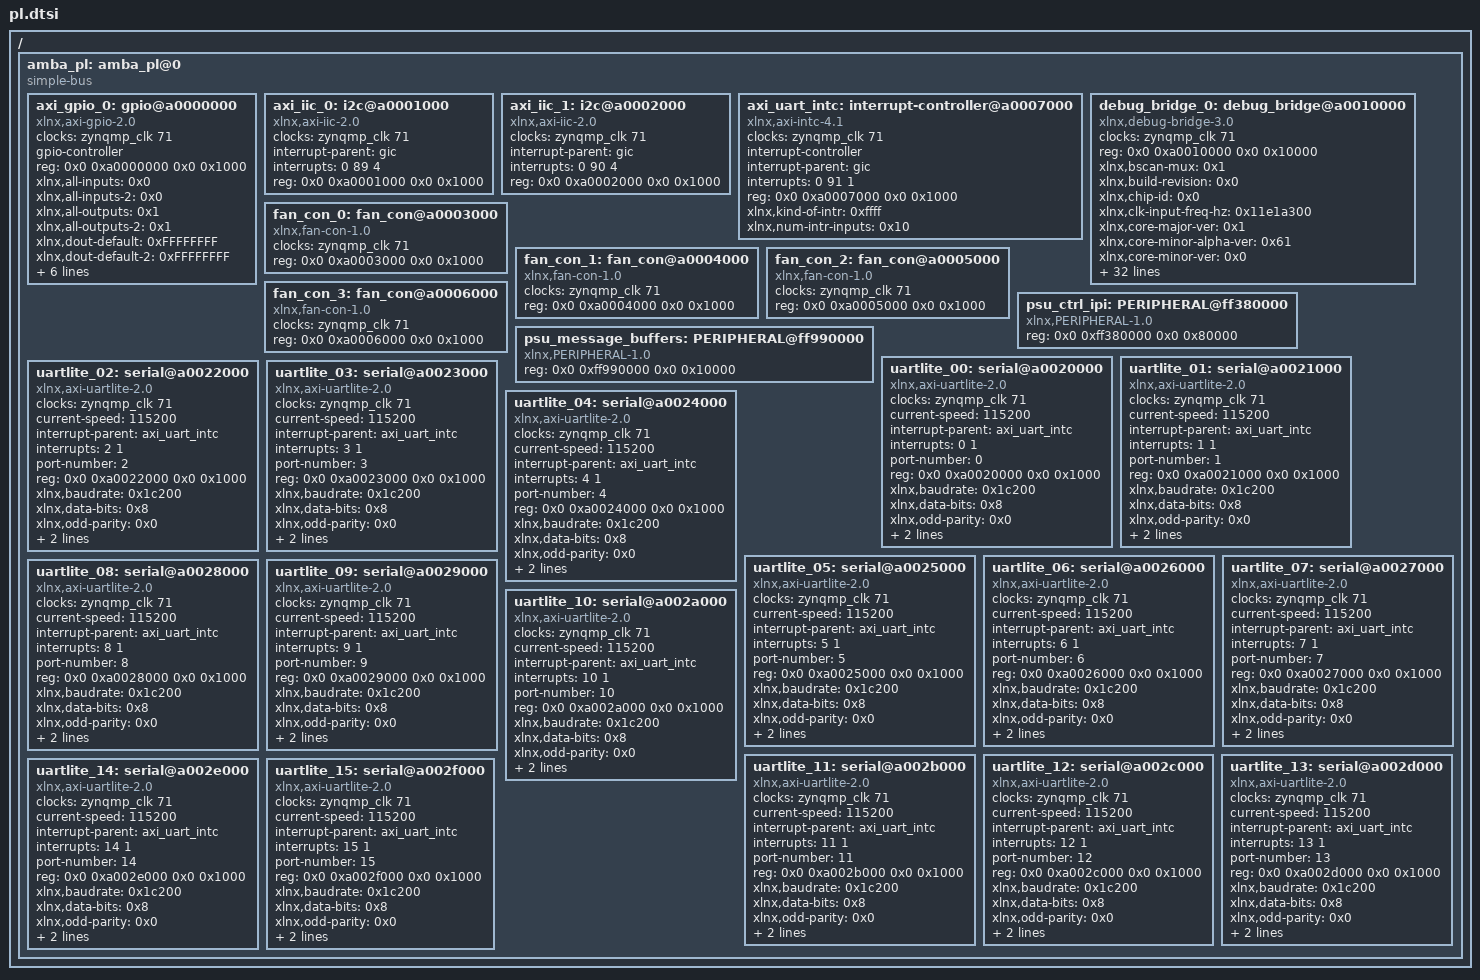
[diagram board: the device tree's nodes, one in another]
/*
 * CAUTION: This file is automatically generated by Xilinx.
 * Version: HSI 2019.1
 * Today is: Wed Dec 30 15:23:14 2020
 */


/ {
	amba_pl: amba_pl@0 {
		#address-cells = <2>;
		#size-cells = <2>;
		compatible = "simple-bus";
		ranges ;
		axi_gpio_0: gpio@a0000000 {
			#gpio-cells = <3>;
			clock-names = "s_axi_aclk";
			clocks = <&zynqmp_clk 71>;
			compatible = "xlnx,axi-gpio-2.0", "xlnx,xps-gpio-1.00.a";
			gpio-controller ;
			reg = <0x0 0xa0000000 0x0 0x1000>;
			xlnx,all-inputs = <0x0>;
			xlnx,all-inputs-2 = <0x0>;
			xlnx,all-outputs = <0x1>;
			xlnx,all-outputs-2 = <0x1>;
			xlnx,dout-default = <0xFFFFFFFF>;
			xlnx,dout-default-2 = <0xFFFFFFFF>;
			xlnx,gpio-width = <0x10>;
			xlnx,gpio2-width = <0x2>;
			xlnx,interrupt-present = <0x0>;
			xlnx,is-dual = <0x1>;
			xlnx,tri-default = <0xFFFFFFFF>;
			xlnx,tri-default-2 = <0xFFFFFFFF>;
		};
		axi_iic_0: i2c@a0001000 {
			#address-cells = <1>;
			#size-cells = <0>;
			clock-names = "s_axi_aclk";
			clocks = <&zynqmp_clk 71>;
			compatible = "xlnx,axi-iic-2.0", "xlnx,xps-iic-2.00.a";
			interrupt-names = "iic2intc_irpt";
			interrupt-parent = <&gic>;
			interrupts = <0 89 4>;
			reg = <0x0 0xa0001000 0x0 0x1000>;
		};
		axi_iic_1: i2c@a0002000 {
			#address-cells = <1>;
			#size-cells = <0>;
			clock-names = "s_axi_aclk";
			clocks = <&zynqmp_clk 71>;
			compatible = "xlnx,axi-iic-2.0", "xlnx,xps-iic-2.00.a";
			interrupt-names = "iic2intc_irpt";
			interrupt-parent = <&gic>;
			interrupts = <0 90 4>;
			reg = <0x0 0xa0002000 0x0 0x1000>;
		};
		axi_uart_intc: interrupt-controller@a0007000 {
			#interrupt-cells = <2>;
			clock-names = "s_axi_aclk";
			clocks = <&zynqmp_clk 71>;
			compatible = "xlnx,axi-intc-4.1", "xlnx,xps-intc-1.00.a";
			interrupt-controller ;
			interrupt-names = "irq";
			interrupt-parent = <&gic>;
			interrupts = <0 91 1>;
			reg = <0x0 0xa0007000 0x0 0x1000>;
			xlnx,kind-of-intr = <0xffff>;
			xlnx,num-intr-inputs = <0x10>;
		};
		debug_bridge_0: debug_bridge@a0010000 {
			/* This is a place holder node for a custom IP, user may need to update the entries */
			clock-names = "s_axi_aclk";
			clocks = <&zynqmp_clk 71>;
			compatible = "xlnx,debug-bridge-3.0";
			reg = <0x0 0xa0010000 0x0 0x10000>;
			xlnx,bscan-mux = <0x1>;
			xlnx,build-revision = <0x0>;
			xlnx,chip-id = <0x0>;
			xlnx,clk-input-freq-hz = <0x11e1a300>;
			xlnx,core-major-ver = <0x1>;
			xlnx,core-minor-alpha-ver = <0x61>;
			xlnx,core-minor-ver = <0x0>;
			xlnx,core-type = <0x1>;
			xlnx,dclk-has-reset = <0x0>;
			xlnx,debug-mode = <0x3>;
			xlnx,design-type = <0x0>;
			xlnx,device-family = <0x0>;
			xlnx,en-bscanid-vec = "false";
			xlnx,en-int-sim = <0x1>;
			xlnx,en-passthrough = <0x0>;
			xlnx,enable-clk-divider = "false";
			xlnx,fifo-style = "SUBCORE";
			xlnx,ir-id-instr = <0x0>;
			xlnx,ir-user1-instr = <0x0>;
			xlnx,ir-width = <0x0>;
			xlnx,major-version = <0xe>;
			xlnx,master-intf-type = <0x1>;
			xlnx,minor-version = <0x1>;
			xlnx,num-bs-master = <0x0>;
			xlnx,pcie-ext-cfg-base-addr = <0x400>;
			xlnx,pcie-ext-cfg-next-ptr = <0x000>;
			xlnx,pcie-ext-cfg-vsec-id = <0x0008>;
			xlnx,pcie-ext-cfg-vsec-length = <0x020>;
			xlnx,pcie-ext-cfg-vsec-rev-id = <0x0>;
			xlnx,tck-clock-ratio = <0x14>;
			xlnx,two-prim-mode = "false";
			xlnx,use-bufr = <0x0>;
			xlnx,use-ext-bscan = "true";
			xlnx,use-softbscan = <0x1>;
			xlnx,use-startup-clk = "false";
			xlnx,user-scan-chain = <0x1>;
			xlnx,xsdb-num-slaves = <0x0>;
			xlnx,xvc-hw-id = <0x0001>;
			xlnx,xvc-sw-id = <0x0001>;
		};
		fan_con_0: fan_con@a0003000 {
			/* This is a place holder node for a custom IP, user may need to update the entries */
			clock-names = "clk_100m";
			clocks = <&zynqmp_clk 71>;
			compatible = "xlnx,fan-con-1.0";
			reg = <0x0 0xa0003000 0x0 0x1000>;
		};
		fan_con_1: fan_con@a0004000 {
			/* This is a place holder node for a custom IP, user may need to update the entries */
			clock-names = "clk_100m";
			clocks = <&zynqmp_clk 71>;
			compatible = "xlnx,fan-con-1.0";
			reg = <0x0 0xa0004000 0x0 0x1000>;
		};
		fan_con_2: fan_con@a0005000 {
			/* This is a place holder node for a custom IP, user may need to update the entries */
			clock-names = "clk_100m";
			clocks = <&zynqmp_clk 71>;
			compatible = "xlnx,fan-con-1.0";
			reg = <0x0 0xa0005000 0x0 0x1000>;
		};
		fan_con_3: fan_con@a0006000 {
			/* This is a place holder node for a custom IP, user may need to update the entries */
			clock-names = "clk_100m";
			clocks = <&zynqmp_clk 71>;
			compatible = "xlnx,fan-con-1.0";
			reg = <0x0 0xa0006000 0x0 0x1000>;
		};
		psu_ctrl_ipi: PERIPHERAL@ff380000 {
			/* This is a place holder node for a custom IP, user may need to update the entries */
			compatible = "xlnx,PERIPHERAL-1.0";
			reg = <0x0 0xff380000 0x0 0x80000>;
		};
		psu_message_buffers: PERIPHERAL@ff990000 {
			/* This is a place holder node for a custom IP, user may need to update the entries */
			compatible = "xlnx,PERIPHERAL-1.0";
			reg = <0x0 0xff990000 0x0 0x10000>;
		};
		uartlite_00: serial@a0020000 {
			clock-names = "s_axi_aclk";
			clocks = <&zynqmp_clk 71>;
			compatible = "xlnx,axi-uartlite-2.0", "xlnx,xps-uartlite-1.00.a";
			current-speed = <115200>;
			device_type = "serial";
			interrupt-names = "interrupt";
			interrupt-parent = <&axi_uart_intc>;
			interrupts = <0 1>;
			port-number = <0>;
			reg = <0x0 0xa0020000 0x0 0x1000>;
			xlnx,baudrate = <0x1c200>;
			xlnx,data-bits = <0x8>;
			xlnx,odd-parity = <0x0>;
			xlnx,s-axi-aclk-freq-hz-d = "99.999001";
			xlnx,use-parity = <0x0>;
		};
		uartlite_01: serial@a0021000 {
			clock-names = "s_axi_aclk";
			clocks = <&zynqmp_clk 71>;
			compatible = "xlnx,axi-uartlite-2.0", "xlnx,xps-uartlite-1.00.a";
			current-speed = <115200>;
			device_type = "serial";
			interrupt-names = "interrupt";
			interrupt-parent = <&axi_uart_intc>;
			interrupts = <1 1>;
			port-number = <1>;
			reg = <0x0 0xa0021000 0x0 0x1000>;
			xlnx,baudrate = <0x1c200>;
			xlnx,data-bits = <0x8>;
			xlnx,odd-parity = <0x0>;
			xlnx,s-axi-aclk-freq-hz-d = "99.999001";
			xlnx,use-parity = <0x0>;
		};
		uartlite_02: serial@a0022000 {
			clock-names = "s_axi_aclk";
			clocks = <&zynqmp_clk 71>;
			compatible = "xlnx,axi-uartlite-2.0", "xlnx,xps-uartlite-1.00.a";
			current-speed = <115200>;
			device_type = "serial";
			interrupt-names = "interrupt";
			interrupt-parent = <&axi_uart_intc>;
			interrupts = <2 1>;
			port-number = <2>;
			reg = <0x0 0xa0022000 0x0 0x1000>;
			xlnx,baudrate = <0x1c200>;
			xlnx,data-bits = <0x8>;
			xlnx,odd-parity = <0x0>;
			xlnx,s-axi-aclk-freq-hz-d = "99.999001";
			xlnx,use-parity = <0x0>;
		};
		uartlite_03: serial@a0023000 {
			clock-names = "s_axi_aclk";
			clocks = <&zynqmp_clk 71>;
			compatible = "xlnx,axi-uartlite-2.0", "xlnx,xps-uartlite-1.00.a";
			current-speed = <115200>;
			device_type = "serial";
			interrupt-names = "interrupt";
			interrupt-parent = <&axi_uart_intc>;
			interrupts = <3 1>;
			port-number = <3>;
			reg = <0x0 0xa0023000 0x0 0x1000>;
			xlnx,baudrate = <0x1c200>;
			xlnx,data-bits = <0x8>;
			xlnx,odd-parity = <0x0>;
			xlnx,s-axi-aclk-freq-hz-d = "99.999001";
			xlnx,use-parity = <0x0>;
		};
		uartlite_04: serial@a0024000 {
			clock-names = "s_axi_aclk";
			clocks = <&zynqmp_clk 71>;
			compatible = "xlnx,axi-uartlite-2.0", "xlnx,xps-uartlite-1.00.a";
			current-speed = <115200>;
			device_type = "serial";
			interrupt-names = "interrupt";
			interrupt-parent = <&axi_uart_intc>;
			interrupts = <4 1>;
			port-number = <4>;
			reg = <0x0 0xa0024000 0x0 0x1000>;
			xlnx,baudrate = <0x1c200>;
			xlnx,data-bits = <0x8>;
			xlnx,odd-parity = <0x0>;
			xlnx,s-axi-aclk-freq-hz-d = "99.999001";
			xlnx,use-parity = <0x0>;
		};
		uartlite_05: serial@a0025000 {
			clock-names = "s_axi_aclk";
			clocks = <&zynqmp_clk 71>;
			compatible = "xlnx,axi-uartlite-2.0", "xlnx,xps-uartlite-1.00.a";
			current-speed = <115200>;
			device_type = "serial";
			interrupt-names = "interrupt";
			interrupt-parent = <&axi_uart_intc>;
			interrupts = <5 1>;
			port-number = <5>;
			reg = <0x0 0xa0025000 0x0 0x1000>;
			xlnx,baudrate = <0x1c200>;
			xlnx,data-bits = <0x8>;
			xlnx,odd-parity = <0x0>;
			xlnx,s-axi-aclk-freq-hz-d = "99.999001";
			xlnx,use-parity = <0x0>;
		};
		uartlite_06: serial@a0026000 {
			clock-names = "s_axi_aclk";
			clocks = <&zynqmp_clk 71>;
			compatible = "xlnx,axi-uartlite-2.0", "xlnx,xps-uartlite-1.00.a";
			current-speed = <115200>;
			device_type = "serial";
			interrupt-names = "interrupt";
			interrupt-parent = <&axi_uart_intc>;
			interrupts = <6 1>;
			port-number = <6>;
			reg = <0x0 0xa0026000 0x0 0x1000>;
			xlnx,baudrate = <0x1c200>;
			xlnx,data-bits = <0x8>;
			xlnx,odd-parity = <0x0>;
			xlnx,s-axi-aclk-freq-hz-d = "99.999001";
			xlnx,use-parity = <0x0>;
		};
		uartlite_07: serial@a0027000 {
			clock-names = "s_axi_aclk";
			clocks = <&zynqmp_clk 71>;
			compatible = "xlnx,axi-uartlite-2.0", "xlnx,xps-uartlite-1.00.a";
			current-speed = <115200>;
			device_type = "serial";
			interrupt-names = "interrupt";
			interrupt-parent = <&axi_uart_intc>;
			interrupts = <7 1>;
			port-number = <7>;
			reg = <0x0 0xa0027000 0x0 0x1000>;
			xlnx,baudrate = <0x1c200>;
			xlnx,data-bits = <0x8>;
			xlnx,odd-parity = <0x0>;
			xlnx,s-axi-aclk-freq-hz-d = "99.999001";
			xlnx,use-parity = <0x0>;
		};
		uartlite_08: serial@a0028000 {
			clock-names = "s_axi_aclk";
			clocks = <&zynqmp_clk 71>;
			compatible = "xlnx,axi-uartlite-2.0", "xlnx,xps-uartlite-1.00.a";
			current-speed = <115200>;
			device_type = "serial";
			interrupt-names = "interrupt";
			interrupt-parent = <&axi_uart_intc>;
			interrupts = <8 1>;
			port-number = <8>;
			reg = <0x0 0xa0028000 0x0 0x1000>;
			xlnx,baudrate = <0x1c200>;
			xlnx,data-bits = <0x8>;
			xlnx,odd-parity = <0x0>;
			xlnx,s-axi-aclk-freq-hz-d = "99.999001";
			xlnx,use-parity = <0x0>;
		};
		uartlite_09: serial@a0029000 {
			clock-names = "s_axi_aclk";
			clocks = <&zynqmp_clk 71>;
			compatible = "xlnx,axi-uartlite-2.0", "xlnx,xps-uartlite-1.00.a";
			current-speed = <115200>;
			device_type = "serial";
			interrupt-names = "interrupt";
			interrupt-parent = <&axi_uart_intc>;
			interrupts = <9 1>;
			port-number = <9>;
			reg = <0x0 0xa0029000 0x0 0x1000>;
			xlnx,baudrate = <0x1c200>;
			xlnx,data-bits = <0x8>;
			xlnx,odd-parity = <0x0>;
			xlnx,s-axi-aclk-freq-hz-d = "99.999001";
			xlnx,use-parity = <0x0>;
		};
		uartlite_10: serial@a002a000 {
			clock-names = "s_axi_aclk";
			clocks = <&zynqmp_clk 71>;
			compatible = "xlnx,axi-uartlite-2.0", "xlnx,xps-uartlite-1.00.a";
			current-speed = <115200>;
			device_type = "serial";
			interrupt-names = "interrupt";
			interrupt-parent = <&axi_uart_intc>;
			interrupts = <10 1>;
			port-number = <10>;
			reg = <0x0 0xa002a000 0x0 0x1000>;
			xlnx,baudrate = <0x1c200>;
			xlnx,data-bits = <0x8>;
			xlnx,odd-parity = <0x0>;
			xlnx,s-axi-aclk-freq-hz-d = "99.999001";
			xlnx,use-parity = <0x0>;
		};
		uartlite_11: serial@a002b000 {
			clock-names = "s_axi_aclk";
			clocks = <&zynqmp_clk 71>;
			compatible = "xlnx,axi-uartlite-2.0", "xlnx,xps-uartlite-1.00.a";
			current-speed = <115200>;
			device_type = "serial";
			interrupt-names = "interrupt";
			interrupt-parent = <&axi_uart_intc>;
			interrupts = <11 1>;
			port-number = <11>;
			reg = <0x0 0xa002b000 0x0 0x1000>;
			xlnx,baudrate = <0x1c200>;
			xlnx,data-bits = <0x8>;
			xlnx,odd-parity = <0x0>;
			xlnx,s-axi-aclk-freq-hz-d = "99.999001";
			xlnx,use-parity = <0x0>;
		};
		uartlite_12: serial@a002c000 {
			clock-names = "s_axi_aclk";
			clocks = <&zynqmp_clk 71>;
			compatible = "xlnx,axi-uartlite-2.0", "xlnx,xps-uartlite-1.00.a";
			current-speed = <115200>;
			device_type = "serial";
			interrupt-names = "interrupt";
			interrupt-parent = <&axi_uart_intc>;
			interrupts = <12 1>;
			port-number = <12>;
			reg = <0x0 0xa002c000 0x0 0x1000>;
			xlnx,baudrate = <0x1c200>;
			xlnx,data-bits = <0x8>;
			xlnx,odd-parity = <0x0>;
			xlnx,s-axi-aclk-freq-hz-d = "99.999001";
			xlnx,use-parity = <0x0>;
		};
		uartlite_13: serial@a002d000 {
			clock-names = "s_axi_aclk";
			clocks = <&zynqmp_clk 71>;
			compatible = "xlnx,axi-uartlite-2.0", "xlnx,xps-uartlite-1.00.a";
			current-speed = <115200>;
			device_type = "serial";
			interrupt-names = "interrupt";
			interrupt-parent = <&axi_uart_intc>;
			interrupts = <13 1>;
			port-number = <13>;
			reg = <0x0 0xa002d000 0x0 0x1000>;
			xlnx,baudrate = <0x1c200>;
			xlnx,data-bits = <0x8>;
			xlnx,odd-parity = <0x0>;
			xlnx,s-axi-aclk-freq-hz-d = "99.999001";
			xlnx,use-parity = <0x0>;
		};
		uartlite_14: serial@a002e000 {
			clock-names = "s_axi_aclk";
			clocks = <&zynqmp_clk 71>;
			compatible = "xlnx,axi-uartlite-2.0", "xlnx,xps-uartlite-1.00.a";
			current-speed = <115200>;
			device_type = "serial";
			interrupt-names = "interrupt";
			interrupt-parent = <&axi_uart_intc>;
			interrupts = <14 1>;
			port-number = <14>;
			reg = <0x0 0xa002e000 0x0 0x1000>;
			xlnx,baudrate = <0x1c200>;
			xlnx,data-bits = <0x8>;
			xlnx,odd-parity = <0x0>;
			xlnx,s-axi-aclk-freq-hz-d = "99.999001";
			xlnx,use-parity = <0x0>;
		};
		uartlite_15: serial@a002f000 {
			clock-names = "s_axi_aclk";
			clocks = <&zynqmp_clk 71>;
			compatible = "xlnx,axi-uartlite-2.0", "xlnx,xps-uartlite-1.00.a";
			current-speed = <115200>;
			device_type = "serial";
			interrupt-names = "interrupt";
			interrupt-parent = <&axi_uart_intc>;
			interrupts = <15 1>;
			port-number = <15>;
			reg = <0x0 0xa002f000 0x0 0x1000>;
			xlnx,baudrate = <0x1c200>;
			xlnx,data-bits = <0x8>;
			xlnx,odd-parity = <0x0>;
			xlnx,s-axi-aclk-freq-hz-d = "99.999001";
			xlnx,use-parity = <0x0>;
		};
	};
};
